# N575F145_v1 register map
File version: 1.0
Registers are 32-bit, read-write, reset 0x0 unless marked. A register's access mark holds for its fields unless they carry their own. Offsets are from the block's base; [hi:lo] are bit positions; 'fields as' and 'values as' point back to an identical list; <NAME> marks a mode.

## PWMA — PWMA Register Map
Base 0x40040000
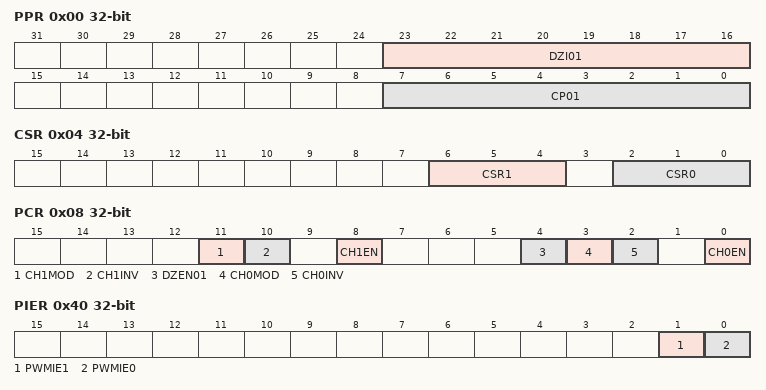
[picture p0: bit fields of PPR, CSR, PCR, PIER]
0x00 PPR — PWM Prescaler Register
  [23:16] DZI01 — Dead Zone Interval Register For Pair Of PWM0 And PWM1. These 8 bits determine dead zone length. The unit time of dead zone length is that from clock selector 0.
  [7:0] CP01 — Clock Pre-scaler. Clock input is divided by (CP01 + 1). If CP01 = 0, then the pre-scaler output clock will be stopped. This implies PWM counter 0 and 1 will also be stopped.
0x04 CSR — PWM Clock Select Register
  [6:4] CSR1 — Timer 1 Clock Source Selection. Value : Input clock divided by. 0 : 2. 1 : 4. 2 : 8. 3 : 16. 4 : 1
  [2:0] CSR0 — Timer 0 Clock Source Selection (Table is as CSR1)
0x08 PCR — PWM Control Register
  [11] CH1MOD — PWM-Timer 1 Auto-reload/One-Shot Mode. Note: A rising transition of this bit will cause CNR1 and CMR1 to be cleared.
    0=One-Shot Mode; 1=Auto-load Mode
  [10] CH1INV — PWM-Timer 1 Output Inverter ON/OFF
    0=Inverter OFF; 1=Inverter ON
  [8] CH1EN — PWM-Timer 1 Enable/Disable Start Run
    0=Stop PWM-Timer 1; 1=Enable PWM-Timer 1 Start/Run
  [4] DZEN01 — Dead-Zone 0 Generator Enable/Disable. Note: When Dead-Zone Generator is enabled, the pair of PWM0 and PWM1 become a complementary pair.
    0=Disable; 1=Enable
  [3] CH0MOD — PWM-Timer 0 Auto-reload/One-Shot Mode. Note: A rising transition of this bit will cause CNR0 and CMR0 to be cleared.
    0=One-Shot Mode; 1=Auto-reload Mode
  [2] CH0INV — PWM-Timer 0 Output Inverter ON/OFF
    0=Inverter OFF; 1=Inverter ON
  [0] CH0EN — PWM-Timer 0 Enable/Disable Start Run
    0=Stop PWM-Timer 0 Running; 1=Enable PWM-Timer 0 Start/Run
0x0C CNR0 — PWM Counter Register 0
  [15:0] CNR — PWM Counter/Timer Reload Value. CNR determines the PWM period. PWM frequency = PWM01_CLK/(prescale+1)*(clock divider)/(CNR+1); Duty ratio = (CMR+1)/(CNR+1). CMR > = CNR: PWM output is always high. CMR < CNR: PWM low width = (CNR-CMR) unit; PWM high width = (CMR+1) unit. CMR = 0: PWM low width = (CNR) unit; PWM high width = 1 unit (Unit = one PWM clock cycle). Note: Any write to CNR will take effect in next PWM cycle.
0x10 CMR0 — PWM Comparator Register 0
  [15:0] CMR — PWM Comparator Register. CMR determines the PWM duty cycle. PWM frequency = PWM01_CLK/(prescale+1)*(clock divider)/(CNR+1); Duty Cycle = (CMR+1)/(CNR+1). CMR > = CNR: PWM output is always high. CMR < CNR: PWM low width = (CNR-CMR) unit; PWM high width = (CMR+1) unit. CMR = 0: PWM low width = (CNR) unit; PWM high width = 1 unit (Unit = one PWM clock cycle). Note: Any write to CMR will take effect in next PWM cycle.
0x14 PDR0 ro — PWM Data Register 0
  [15:0] PDR — PWM Data Register. Reports the current value of the 16-bit down counter.
0x18 CNR1 — PWM Counter Register 0
  fields as CNR0
0x1C CMR1 — PWM Comparator Register 0
  fields as CMR0
0x20 PDR1 ro — PWM Data Register 0
  fields as PDR0
0x40 PIER — PWM Interrupt Enable Register
  [1] PWMIE1 — PWM Timer 1 Interrupt Enable
    0=Disable; 1=Enable
  [0] PWMIE0 — PWM Timer 0 Interrupt Enable
    0=Disable; 1=Enable
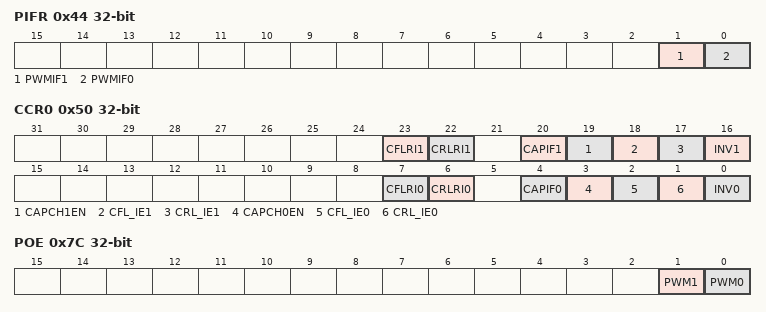
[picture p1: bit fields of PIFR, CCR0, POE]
0x44 PIFR — PWM Interrupt Flag Register
  [1] PWMIF1 — PWM Timer 1 Interrupt Flag. Flag is set by hardware when PWM1 down counter reaches zero, software can clear this bit by writing '1' to it.
  [0] PWMIF0 — PWM Timer 0 Interrupt Flag. Flag is set by hardware when PWM0 down counter reaches zero, software can clear this bit by writing '1' to it.
0x50 CCR0 — Capture Control Register 0
  [23] CFLRI1 — CFLR1 Latched Indicator Bit. When input channel 1 has a falling transition, CFLR1 was latched with the value of PWM down-counter and this bit is set by hardware, software can clear this bit by writing a zero to it.
  [22] CRLRI1 — CRLR1 Latched Indicator Bit. When input channel 1 has a rising transition, CRLR1 was latched with the value of PWM down-counter and this bit is set by hardware, software can clear this bit by writing a zero to it.
  [20] CAPIF1 — Capture1 Interrupt Indication Flag. If channel 1 rising latch interrupt is enabled (CRL_IE1 = 1), a rising transition at input channel 1 will result in CAPIF1 to high; Similarly, a falling transition will cause CAPIF1 to be set high if channel 1 falling latch interrupt is enabled (CFL_IE1 = 1). This flag is cleared by software writing a '1' to it.
  [19] CAPCH1EN — Capture Channel 1 Transition Enable/Disable. When enabled, Capture function latches the PMW-counter to CRLR (Rising latch) and CFLR (Falling latch) registers on input edge transition. When disabled, Capture function is inactive as is interrupt.
    0=Disable capture function on channel 1; 1=Enable capture function on channel 1
  [18] CFL_IE1 — Channel 1 Falling Latch Interrupt Enable. When enabled, capture block generates an interrupt on falling edge of input.
    0=Disable falling edge latch interrupt; 1=Enable falling edge latch interrupt
  [17] CRL_IE1 — Channel 1 Rising Latch Interrupt Enable. When enabled, capture block generates an interrupt on rising edge of input.
    0=Disable rising edge latch interrupt; 1=Enable rising edge latch interrupt
  [16] INV1 — Channel 1 Inverter ON/OFF
    0=Inverter OFF; 1=Inverter ON. Reverse the input signal from GPIO before Capture timer
  [7] CFLRI0 — CFLR0 Latched Indicator Bit. When input channel 0 has a falling transition, CFLR0 was latched with the value of PWM down-counter and this bit is set by hardware, software can clear this bit by writing a zero to it.
  [6] CRLRI0 — CRLR0 Latched Indicator Bit. When input channel 0 has a rising transition, CRLR0 was latched with the value of PWM down-counter and this bit is set by hardware, software can clear this bit by writing a zero to it.
  [4] CAPIF0 — Capture0 Interrupt Indication Flag. If channel 0 rising latch interrupt is enabled (CRL_IE0 = 1), a rising transition at input channel 0 will result in CAPIF0 to high; Similarly, a falling transition will cause CAPIF0 to be set high if channel 0 falling latch interrupt is enabled (CFL_IE0 = 1). This flag is cleared by software writing a '1' to it.
  [3] CAPCH0EN — Capture Channel 0 transition Enable/Disable. When enabled, Capture function latches the PMW-counter to CRLR (Rising latch) and CFLR (Falling latch) registers on input edge transition. When disabled, Capture function is inactive as is interrupt.
    0=Disable capture function on channel 0; 1=Enable capture function on channel 0
  [2] CFL_IE0 — Channel 0 Falling Latch Interrupt Enable ON/OFF. When enabled, capture block generates an interrupt on falling edge of input.
    0=Disable falling latch interrupt; 1=Enable falling latch interrupt
  [1] CRL_IE0 — Channel 0 Rising Latch Interrupt Enable ON/OFF. When enabled, capture block generates an interrupt on rising edge of input.
    0=Disable rising latch interrupt; 1=Enable rising latch interrupt
  [0] INV0 — Channel 0 Inverter ON/OFF
    values as INV1
0x58 CRLR0 ro — Capture Rising Latch Register (Channel 0)
  [15:0] CRLR — Capture Rising Latch Register. In Capture mode, this register is latched with the value of the PWM counter on a rising edge of the input signal.
0x5C CFLR0 ro — Capture Falling Latch Register (Channel 0)
  [15:0] CFLR — Capture Falling Latch Register. In Capture mode, this register is latched with the value of the PWM counter on a falling edge of the input signal.
0x60 CRLR1 ro — Capture Rising Latch Register (Channel 0)
  fields as CRLR0
0x64 CFLR1 ro — Capture Falling Latch Register (Channel 0)
  fields as CFLR0
0x78 CAPENR — Capture Input Enable Register
  [3:0] CAPENR — Capture Input Enable Register. 0 : OFF (GPA[13:12] pin input disconnected from Capture block). 1 : ON (GPA[13:12] pin, if in PWM alternative function, will be configured as an input and fed to capture function). CAPENR[1:0]. Bit 10. Bit x1 : Capture channel 0 is from GPA [12]. Bit 1x : Capture channel 1 is from GPA [13]
0x7C POE — PWM Output Enable Register for PWM0~PWM1
  [1] PWM1 — PWM1 Output Enable Register. Note: The corresponding GPIO pin also must be switched to PWM function (refer to GPA_ALT Table 57)
    0=Disable PWM1 output to pin; 1=Enable PWM1 output to pin
  [0] PWM0 — PWM0 Output Enable Register. Note: The corresponding GPIO pin also must be switched to PWM function (refer to GPA_ALT Table 57)
    0=Disable PWM0 output to pin; 1=Enable PWM0 output to pin
